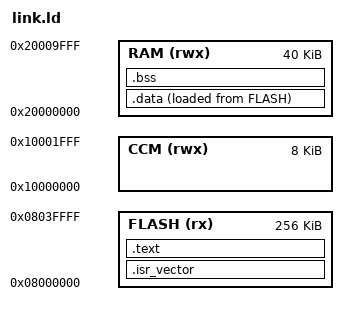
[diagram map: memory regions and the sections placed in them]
/* STM32F303 Linker Script */
MEMORY
{
    FLASH (rx)  : ORIGIN = 0x08000000, LENGTH = 256K
    RAM (rwx)   : ORIGIN = 0x20000000, LENGTH = 40K
    CCM (rwx)   : ORIGIN = 0x10000000, LENGTH = 8K
}

_estack = ORIGIN(RAM) + LENGTH(RAM);

SECTIONS
{
    .isr_vector :
    {
        . = ALIGN(4);
        KEEP(*(.isr_vector))
        . = ALIGN(4);
    } > FLASH

    .text :
    {
        . = ALIGN(4);
        *(.text)
        *(.text*)
        *(.rodata)
        *(.rodata*)
        . = ALIGN(4);
    } > FLASH

    .data :
    {
        . = ALIGN(4);
        _sdata = .;
        *(.data)
        *(.data*)
        . = ALIGN(4);
        _edata = .;
    } > RAM AT > FLASH

    .bss :
    {
        . = ALIGN(4);
        _sbss = .;
        *(.bss)
        *(.bss*)
        *(COMMON)
        . = ALIGN(4);
        _ebss = .;
    } > RAM
}
